# PN74xxAU register map
File version: 2
CPU: CM0 r0p0, little endian, no MPU, no FPU, 2 interrupt priority bits
Registers are 32-bit, read-write, reset 0x0 unless marked. A register's access mark holds for its fields unless they carry their own. Offsets are from the block's base; [hi:lo] are bit positions.

## ClockGen
Base 0x40010000
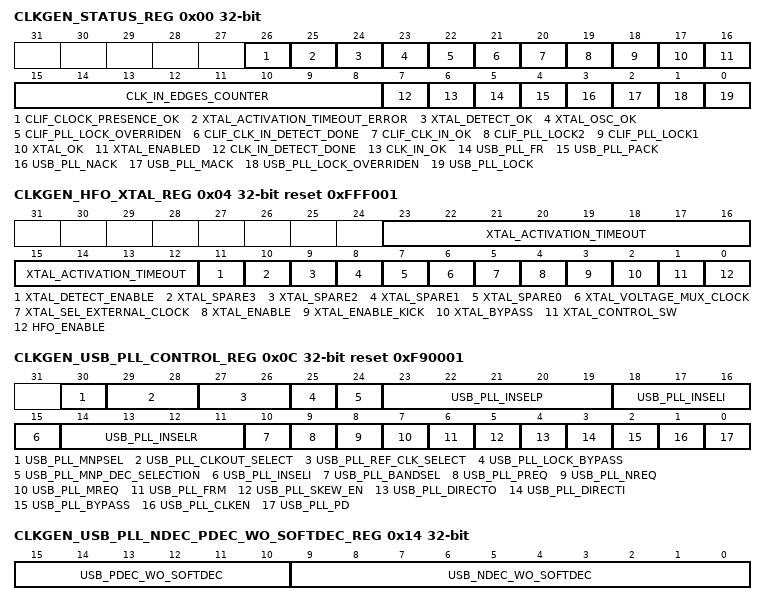
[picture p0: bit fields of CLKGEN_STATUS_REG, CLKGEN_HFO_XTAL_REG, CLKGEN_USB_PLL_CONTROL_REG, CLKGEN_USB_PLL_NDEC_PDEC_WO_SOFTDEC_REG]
0x00 CLKGEN_STATUS_REG ro — CLKGEN Status Register (RO)
  [26] CLIF_CLOCK_PRESENCE_OK — Indicates the status of clkgen_clif_pll_lock2_o signal.
  [25] XTAL_ACTIVATION_TIMEOUT_ERROR — High if timeout for XTAL Activation is reached
  [24] XTAL_DETECT_OK — Indicates the presence of clock signal on clk_xtal if xtal_detect_enable is set.
  [23] XTAL_OSC_OK — MRA2 Only - high to indicate the clock is ready
  [22] CLIF_PLL_LOCK_OVERRIDEN — MRA2 Only - NFCC1036 - High if pll_lock2 OR pll_bypass_lock2 is high
  [21] CLIF_CLK_IN_DETECT_DONE — High if detection is done.
  [20] CLIF_CLK_IN_OK — PLL input clok detector ok signal. High if clk_in is present
  [19] CLIF_PLL_LOCK2 — Lock detector Output for 2nd PLL
  [18] CLIF_PLL_LOCK1 — Lock detector Output for 1st PLL. If lock1 is high then PLL2 should be enabled.
  [17] XTAL_OK — High if XTAL Oscillator is Activated
  [16] XTAL_ENABLED — High if XTAL Oscillator is Enabled
  [15:8] CLK_IN_EDGES_COUNTER — Input Clock Edges Counter Value
  [7] CLK_IN_DETECT_DONE — High if USB_PLL Input Clock is Detected
  [6] CLK_IN_OK — USB_PLL Input Clock Detector OK Status. High if CLK_IN is Present
  [5] USB_PLL_FR — USB_PLL Free Running Detector Status
  [4] USB_PLL_PACK — USB_PLL Post-Divider Ratio Change Acknowledge
  [3] USB_PLL_NACK — USB_PLL Pre-Divider Ratio Change Acknowledge
  [2] USB_PLL_MACK — USB_PLL Feedback Divider Ratio Change Acknowledge
  [1] USB_PLL_LOCK_OVERRIDEN — USB_PLL Lock Overriden Status. High if CLKGEN_STATUS_REG.USB_PLL_lock or CLKGEN_USB_PLL_GLOBAL_CONTROL_REG.USB_PLL_lock_bypass is high.
  [0] USB_PLL_LOCK — USB_PLL Lock Status
0x04 CLKGEN_HFO_XTAL_REG reset 0xFFF001 — CLKGEN HFO and XTAL Control Register (RW)
  [23:12] XTAL_ACTIVATION_TIMEOUT — Set the XTAL Activation Timeout Value (in LFO Clock Cycles + 8) - default value > 10ms
  [11] XTAL_DETECT_ENABLE — Enable the XTAL output clock presence detection if clk_in_detect_enable is low.
  [10] XTAL_SPARE3 — Controls XTAL Spare3
  [9] XTAL_SPARE2 — Controls XTAL Spare2
  [8] XTAL_SPARE1 — Controls XTAL Spare1
  [7] XTAL_SPARE0 — Controls XTAL Pull Down if XTAL_CONTROL_SW='1'
  [6] XTAL_VOLTAGE_MUX_CLOCK — Controls XTAL Voltage Mux
  [5] XTAL_SEL_EXTERNAL_CLOCK — Controls XTAL External Clock Selection if XTAL_CONTROL_SW='1'
  [4] XTAL_ENABLE — Controls XTAL Enable if XTAL_CONTROL_SW='1'
  [3] XTAL_ENABLE_KICK — Controls XTAL Enable Kick if XTAL_CONTROL_SW='1'
  [2] XTAL_BYPASS — Controls XTAL Bypass if XTAL_CONTROL_SW='1'
  [1] XTAL_CONTROL_SW — High to control the XTAL Oscilator by SW
  [0] HFO_ENABLE — Enables the HFO (Activated by default)
0x0C CLKGEN_USB_PLL_CONTROL_REG reset 0xF90001 — CLKGEN USB_PLL Control Register
  [30] USB_PLL_MNPSEL — M,N,P selection values for the Soft Decoder: When Low, M=600,N=113,P=3 and when high, M=92,N=13,P=4
  [29:28] USB_PLL_CLKOUT_SELECT — Selects the Output Clock
  [27:26] USB_PLL_REF_CLK_SELECT — Selects the reference clock for USB PLL
  [25] USB_PLL_LOCK_BYPASS — Bypass the USB_PLL Lock Output Status. Set to '1' the CLKGEN_STATUS_REG.USB_PLL_lock_overriden status bit.
  [24] USB_PLL_MNP_DEC_SELECTION — When High, M,N,P divider ratio are not coming from the Soft Decoder but from the CLKGEN_USB_PLL_MDEC_WO_SOFTDEC and CLKGEN_USB_PLL_NDEC_PDEC_WO_SOFTDEC registers
  [23:19] USB_PLL_INSELP — Select the Bandwidth (don't care if USB_PLL_BANDSEL='0')
  [18:15] USB_PLL_INSELI — Select the Bandwidth (don't care if USB_PLL_BANDSEL='0')
  [14:11] USB_PLL_INSELR — Select the Bandwidth (don't care if USB_PLL_BANDSEL='0')
  [10] USB_PLL_BANDSEL — Bandwidth Adjustement (to modify externally the bandwidth of the USB_PLL)
  [9] USB_PLL_PREQ — USB_PLL Post-Divider Ratio Change Request
  [8] USB_PLL_NREQ — USB_PLL Pre-Divider Ratio Change Request
  [7] USB_PLL_MREQ — USB_PLL Feedback Divider Ratio Change Request
  [6] USB_PLL_FRM — USB_PLL Free Running Mode
  [5] USB_PLL_SKEW_EN — USB_PLL Skew Mode
  [4] USB_PLL_DIRECTO — Bypass of the USB_PLL Post-Divider
  [3] USB_PLL_DIRECTI — Bypass of the USB_PLL Pre-Divider
  [2] USB_PLL_BYPASS — Bypass of the USB_PLL (clkout=clkin)
  [1] USB_PLL_CLKEN — Enable the USB_PLL Output Clock
  [0] USB_PLL_PD — USB_PLL Into Power Down
0x10 CLKGEN_USB_PLL_MDEC_WO_SOFTDEC_REG — CLKGEN M Dividers Ratio Values Register
  [16:0] USB_MDEC_WO_SOFTDEC — Divider Ratio Code for M-divider when Soft Decoder is not used
0x14 CLKGEN_USB_PLL_NDEC_PDEC_WO_SOFTDEC_REG — CLKGEN N and P Dividers Ratio Values Register
  [15:10] USB_PDEC_WO_SOFTDEC — Divider Ratio Code for P-divider when Soft Decoder is not used
  [9:0] USB_NDEC_WO_SOFTDEC — Divider Ratio Code for N-divider when Soft Decoder is not used
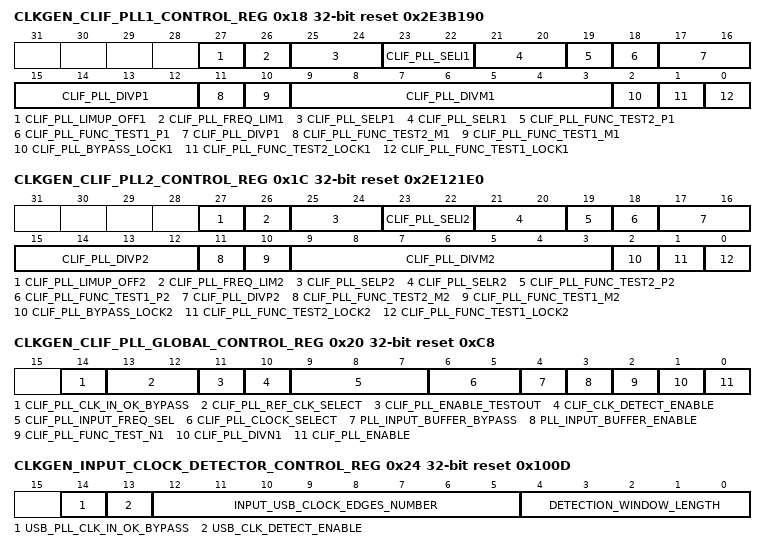
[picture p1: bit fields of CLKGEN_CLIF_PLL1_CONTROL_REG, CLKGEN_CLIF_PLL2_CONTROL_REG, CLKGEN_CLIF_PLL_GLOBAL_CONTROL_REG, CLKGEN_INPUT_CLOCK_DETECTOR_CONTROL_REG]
0x18 CLKGEN_CLIF_PLL1_CONTROL_REG reset 0x2E3B190 — Clif pll usage configurations
  [27] CLIF_PLL_LIMUP_OFF1 — Pulse Limiter for CLIF_PLL 1
  [26] CLIF_PLL_FREQ_LIM1 — Frequency Limiter for CLIF_PLL 1
  [25:24] CLIF_PLL_SELP1 — pins to select the BW of CLIF_PLL 1
  [23:22] CLIF_PLL_SELI1 — pins to select the BW of CLIF_PLL 1
  [21:20] CLIF_PLL_SELR1 — pins to select the BW of CLIF_PLL 1
  [19] CLIF_PLL_FUNC_TEST2_P1 — Enable functional CLIF_PLL chain test of divider P1
  [18] CLIF_PLL_FUNC_TEST1_P1 — Enable functional divider test of divider P1
  [17:12] CLIF_PLL_DIVP1 — Feedback divider ratio P1
  [11] CLIF_PLL_FUNC_TEST2_M1 — Enable functional CLIF_PLL test chain of divider M1
  [10] CLIF_PLL_FUNC_TEST1_M1 — Enable functional divider test of divider M1
  [9:3] CLIF_PLL_DIVM1 — Feedback divider ratio M1
  [2] CLIF_PLL_BYPASS_LOCK1 — Bypass of Lock1
  [1] CLIF_PLL_FUNC_TEST2_LOCK1 — Enable functional CLIF_PLL test chain of lock detector 1
  [0] CLIF_PLL_FUNC_TEST1_LOCK1 — Enable functional divider test of lock detector 1
0x1C CLKGEN_CLIF_PLL2_CONTROL_REG reset 0x2E121E0 — Clif pll usage configurations
  [27] CLIF_PLL_LIMUP_OFF2 — Pulse Limiter for CLIF_PLL 2
  [26] CLIF_PLL_FREQ_LIM2 — Frequency Limiter for CLIF_PLL 2
  [25:24] CLIF_PLL_SELP2 — pins to select the BW of CLIF_PLL 2
  [23:22] CLIF_PLL_SELI2 — pins to select the BW of CLIF_PLL 2
  [21:20] CLIF_PLL_SELR2 — pins to select the BW of CLIF_PLL 2
  [19] CLIF_PLL_FUNC_TEST2_P2 — Enable functional CLIF_PLL chain test of divider P2
  [18] CLIF_PLL_FUNC_TEST1_P2 — Enable functional divider test of divider P2
  [17:12] CLIF_PLL_DIVP2 — Feedback divider ratio P2
  [11] CLIF_PLL_FUNC_TEST2_M2 — Enable functional CLIF_PLL test chain of divider M2
  [10] CLIF_PLL_FUNC_TEST1_M2 — Enable functional divider test of divider M2
  [9:3] CLIF_PLL_DIVM2 — Feedback divider ratio M2
  [2] CLIF_PLL_BYPASS_LOCK2 — Bypass of Lock2
  [1] CLIF_PLL_FUNC_TEST2_LOCK2 — Enable functional CLIF_PLL test chain of lock detector 2
  [0] CLIF_PLL_FUNC_TEST1_LOCK2 — Enable functional divider test of lock detector 2
0x20 CLKGEN_CLIF_PLL_GLOBAL_CONTROL_REG reset 0xC8 — Clif pll integration configurations
  [14] CLIF_PLL_CLK_IN_OK_BYPASS — CLIF pll clk_in detection override
  [13:12] CLIF_PLL_REF_CLK_SELECT — CLIF_PLL input clock selector. 00:clk; 01: clk_xtal; 10:clk_hfo_40; 11: clock recovery
  [11] CLIF_PLL_ENABLE_TESTOUT — high to enable the CLIF_PLL output to be on the SMX_IF_pad. Low for HiZ
  [10] CLIF_CLK_DETECT_ENABLE — Enables CLIF_PLL input clock detector (clk_in). Higher prio than xtal_detect_enable.
  [9:7] CLIF_PLL_INPUT_FREQ_SEL — Select input frequency for the CLIF_PLL: 13, 19,2, 24, 26, 38.4 or 52MHz
  [6:5] CLIF_PLL_CLOCK_SELECT — 00: CLIF_PLL output clock 2; 01:xtal clock;10: CLIF_PLL output clock;11: CLIF_PLL input clock
  [4] PLL_INPUT_BUFFER_BYPASS — high to bypass PLL input buffer( the buffer for clock going into USB pll and intPLL)
  [3] PLL_INPUT_BUFFER_ENABLE — Enable the PLL Input Buffer ( the buffer for clock going into USB pll and intPLL)
  [2] CLIF_PLL_FUNC_TEST_N1 — Enable functional divider test and CLIF_PLL test chain of divider M1
  [1] CLIF_PLL_DIVN1 — Pre-divider selection
  [0] CLIF_PLL_ENABLE — Enable the CLIF_PLL
0x24 CLKGEN_INPUT_CLOCK_DETECTOR_CONTROL_REG reset 0x100D — CLKGEN Input clock Detector Control Register
  [14] USB_PLL_CLK_IN_OK_BYPASS — usb pll clk_in detection override
  [13] USB_CLK_DETECT_ENABLE — Divider Ratio Code for P-divider when Soft Decoder is not used
  [12:5] INPUT_USB_CLOCK_EDGES_NUMBER — Divider Ratio Code for N-divider when Soft Decoder is not used
  [4:0] DETECTION_WINDOW_LENGTH — Divider Ratio Code for N-divider when Soft Decoder is not used
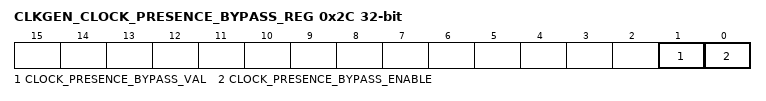
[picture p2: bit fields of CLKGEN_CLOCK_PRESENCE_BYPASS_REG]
0x2C CLKGEN_CLOCK_PRESENCE_BYPASS_REG — Clock presense for clif_pll
  [1] CLOCK_PRESENCE_BYPASS_VAL — Value to apply to clif_pll_lock2_o signal when corresponding enable bit is set.
  [0] CLOCK_PRESENCE_BYPASS_ENABLE — Enables to bypass the clif_pll_lock2_o signal to the value stored in clock_presence_bypass_val
